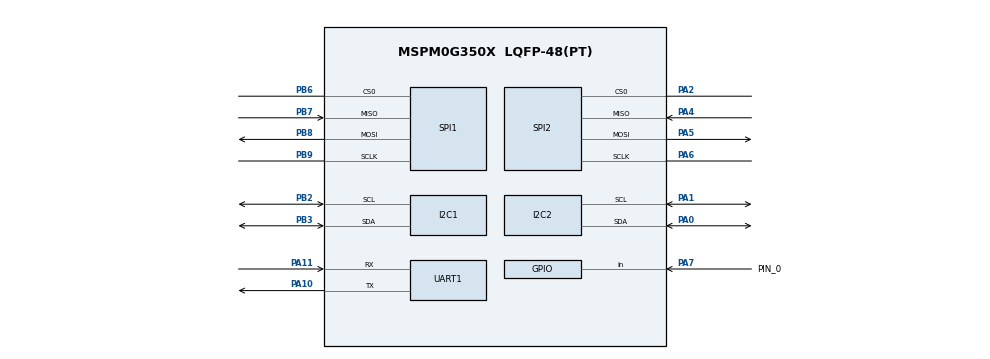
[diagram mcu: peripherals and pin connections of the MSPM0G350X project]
/**
 * @cliArgs --device "MSPM0G350X" --part "Default" --package "LQFP-48(PT)" --product "mspm0_sdk@2.11.00.07"
 * @versions {"tool":"1.28.1+4785"}
 */

/**
 * A test project with the SysConfig setups the two BSPs do not use: an SPI clocked from MFCLK
 * with a divider and an RX timeout DMA trigger, an SPI in peripheral mode, an I2C in target
 * mode only, a PWM with the default instance name whose pins are only suggested, GPIO pins
 * given as port + pin number, a pin with the default name, and a UART with DMA on both sides.
 */
const GPIO   = scripting.addModule("/ti/driverlib/GPIO", {}, false);
const GPIO1  = GPIO.addInstance();
const GPIO2  = GPIO.addInstance();
const I2C    = scripting.addModule("/ti/driverlib/I2C", {}, false);
const I2C1   = I2C.addInstance();
const I2C2   = I2C.addInstance();
const PWM    = scripting.addModule("/ti/driverlib/PWM", {}, false);
const PWM1   = PWM.addInstance();
const SPI    = scripting.addModule("/ti/driverlib/SPI", {}, false);
const SPI1   = SPI.addInstance();
const SPI2   = SPI.addInstance();
const SYSCTL = scripting.addModule("/ti/driverlib/SYSCTL");
const UART   = scripting.addModule("/ti/driverlib/UART", {}, false);
const UART1  = UART.addInstance();

GPIO1.$name                         = "GPIO_LEDS";
GPIO1.port                          = "PORTA";
GPIO1.associatedPins.create(2);
GPIO1.associatedPins[0].$name       = "USER_LED_1";
GPIO1.associatedPins[0].assignedPin = "26";
GPIO1.associatedPins[1].$name       = "USER_LED_2";
GPIO1.associatedPins[1].assignedPin = "27";

GPIO2.$name                              = "GPIO_BTN";
GPIO2.associatedPins.create(1);
GPIO2.associatedPins[0].$name            = "PIN_0";
GPIO2.associatedPins[0].direction        = "INPUT";
GPIO2.associatedPins[0].pin.$assign      = "PA7";

I2C1.$name                     = "I2C_TARGET";
I2C1.basicEnableTarget         = true;
I2C1.basicTargetAddress        = 0x48;
I2C1.peripheral.$assign        = "I2C1";
I2C1.peripheral.sdaPin.$assign = "PB3";
I2C1.peripheral.sclPin.$assign = "PB2";

I2C2.$name                     = "I2C_0";
I2C2.basicEnableController     = true;
I2C2.basicControllerBusSpeed   = 400000;
I2C2.peripheral.$assign        = "I2C0";
I2C2.peripheral.sdaPin.$assign = "PA0";
I2C2.peripheral.sclPin.$assign = "PA1";

PWM1.$name                              = "PWM_0";
PWM1.peripheral.$assign                 = "TIMG0";
PWM1.peripheral.ccp0Pin.$suggestSolution = "PA12";
PWM1.peripheral.ccp1Pin.$suggestSolution = "PA13";

SPI1.$name                                 = "SPI_1";
SPI1.spiClkSrc                             = "MFCLK";
SPI1.spiClkDiv                             = "4";
SPI1.enabledInterrupts                     = ["DMA_DONE_RX","DMA_DONE_TX"];
SPI1.enabledDMAEvent1Triggers              = "DL_SPI_DMA_INTERRUPT_RX_TIMEOUT";
SPI1.enabledDMAEvent2Triggers              = "DL_SPI_DMA_INTERRUPT_TX";
SPI1.peripheral.$assign                    = "SPI1";
SPI1.peripheral.sclkPin.$assign            = "PB9";
SPI1.peripheral.mosiPin.$assign            = "PB8";
SPI1.peripheral.misoPin.$assign            = "PB7";
SPI1.peripheral.cs0Pin.$assign             = "PB6";
SPI1.DMA_CHANNEL_EVENT1.$name              = "DMA_CH_SPI1_RX";
SPI1.DMA_CHANNEL_EVENT1.addressMode        = "f2b";
SPI1.DMA_CHANNEL_EVENT1.srcLength          = "BYTE";
SPI1.DMA_CHANNEL_EVENT1.dstLength          = "BYTE";
SPI1.DMA_CHANNEL_EVENT2.$name              = "DMA_CH_SPI1_TX";
SPI1.DMA_CHANNEL_EVENT2.addressMode        = "b2f";
SPI1.DMA_CHANNEL_EVENT2.srcLength          = "BYTE";
SPI1.DMA_CHANNEL_EVENT2.dstLength          = "BYTE";

SPI2.$name                          = "SPI_PERIPH";
SPI2.mode                           = "PERIPHERAL";
SPI2.peripheral.$assign             = "SPI0";
SPI2.peripheral.sclkPin.$assign     = "PA6";
SPI2.peripheral.mosiPin.$assign     = "PA5";
SPI2.peripheral.misoPin.$assign     = "PA4";
SPI2.peripheral.cs0Pin.$assign      = "PA2";

SYSCTL.MFCLKEn = true;

UART1.$name                             = "UART_0";
UART1.targetBaudRate                    = 115200;
UART1.enableDMATX                       = true;
UART1.enabledDMATXTriggers              = "DL_UART_DMA_INTERRUPT_TX";
UART1.enableDMARX                       = true;
UART1.enabledDMARXTriggers              = "DL_UART_DMA_INTERRUPT_RX";
UART1.peripheral.$assign                = "UART0";
UART1.peripheral.rxPin.$assign          = "PA11";
UART1.peripheral.txPin.$assign          = "PA10";
UART1.DMA_CHANNEL_TX.$name              = "DMA_CH_UART0_TX";
UART1.DMA_CHANNEL_TX.addressMode        = "b2f";
UART1.DMA_CHANNEL_TX.srcLength          = "BYTE";
UART1.DMA_CHANNEL_TX.dstLength          = "BYTE";
UART1.DMA_CHANNEL_RX.$name              = "DMA_CH_UART0_RX";
UART1.DMA_CHANNEL_RX.addressMode        = "f2b";
UART1.DMA_CHANNEL_RX.srcLength          = "BYTE";
UART1.DMA_CHANNEL_RX.dstLength          = "BYTE";
